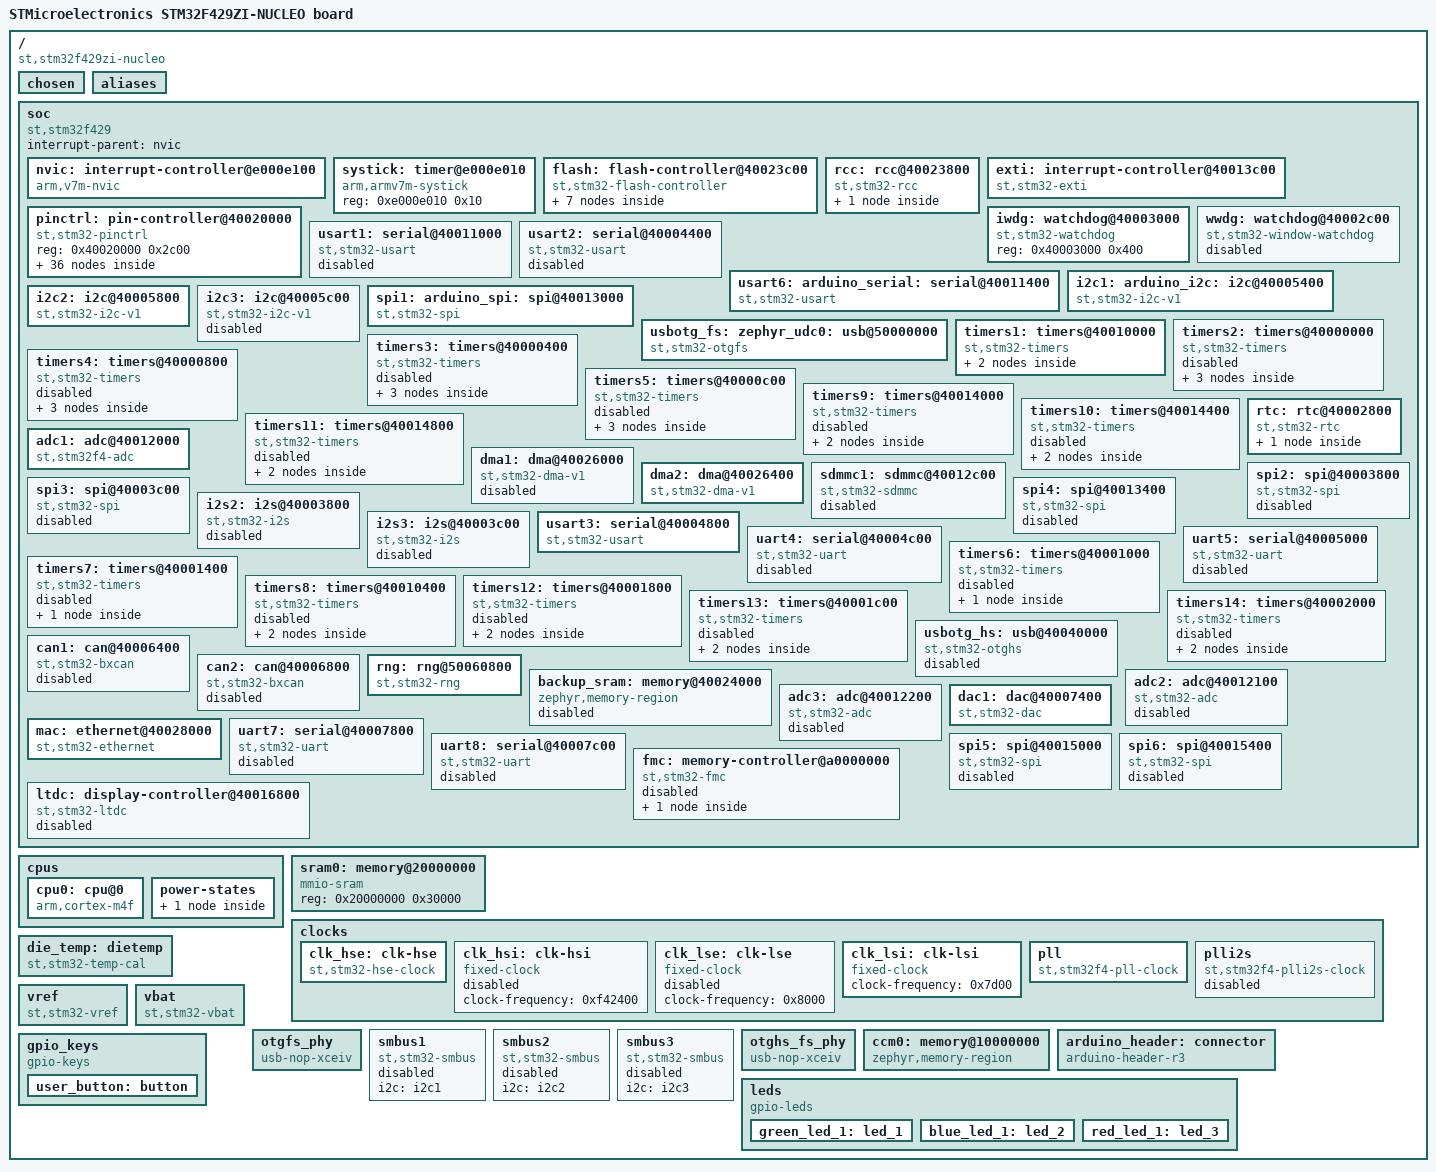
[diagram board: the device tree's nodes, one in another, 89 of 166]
/dts-v1/;

/ {
	#address-cells = < 0x1 >;
	#size-cells = < 0x1 >;
	model = "STMicroelectronics STM32F429ZI-NUCLEO board";
	compatible = "st,stm32f429zi-nucleo";
	chosen {
		zephyr,flash-controller = &flash;
		zephyr,cortex-m-idle-timer = &rtc;
		zephyr,entropy = &rng;
		zephyr,console = &usart3;
		zephyr,shell-uart = &usart3;
		zephyr,sram = &sram0;
		zephyr,flash = &flash0;
		zephyr,ccm = &ccm0;
		zephyr,code-partition = &slot0_partition;
	};
	aliases {
		led0 = &green_led_1;
		led1 = &blue_led_1;
		led2 = &red_led_1;
		sw0 = &user_button;
		watchdog0 = &iwdg;
		die-temp0 = &die_temp;
		volt-sensor0 = &vref;
		volt-sensor1 = &vbat;
	};
	soc {
		#address-cells = < 0x1 >;
		#size-cells = < 0x1 >;
		compatible = "st,stm32f429", "st,stm32f4", "simple-bus";
		interrupt-parent = < &nvic >;
		ranges;
		nvic: interrupt-controller@e000e100 {
			#address-cells = < 0x1 >;
			compatible = "arm,v7m-nvic";
			reg = < 0xe000e100 0xc00 >;
			interrupt-controller;
			#interrupt-cells = < 0x2 >;
			arm,num-irq-priority-bits = < 0x4 >;
			phandle = < 0x1 >;
		};
		systick: timer@e000e010 {
			compatible = "arm,armv7m-systick";
			reg = < 0xe000e010 0x10 >;
		};
		flash: flash-controller@40023c00 {
			compatible = "st,stm32-flash-controller", "st,stm32f4-flash-controller";
			reg = < 0x40023c00 0x400 >;
			interrupts = < 0x4 0x0 >;
			#address-cells = < 0x1 >;
			#size-cells = < 0x1 >;
			flash0: flash@8000000 {
				compatible = "st,stm32f4-nv-flash", "st,stm32-nv-flash", "soc-nv-flash";
				write-block-size = < 0x1 >;
				max-erase-time = < 0xfa0 >;
				reg = < 0x8000000 0x200000 >;
				partitions {
					compatible = "fixed-partitions";
					#address-cells = < 0x1 >;
					#size-cells = < 0x1 >;
					boot_partition: partition@0 {
						label = "mcuboot";
						reg = < 0x0 0x10000 >;
						read-only;
					};
					storage_partition: partition@10000 {
						label = "storage";
						reg = < 0x10000 0x10000 >;
					};
					slot0_partition: partition@20000 {
						label = "image-0";
						reg = < 0x20000 0x40000 >;
					};
					slot1_partition: partition@60000 {
						label = "image-1";
						reg = < 0x60000 0x40000 >;
					};
					scratch_partition: partition@a0000 {
						label = "image-scratch";
						reg = < 0xa0000 0x20000 >;
					};
				};
			};
		};
		rcc: rcc@40023800 {
			compatible = "st,stm32-rcc";
			#clock-cells = < 0x2 >;
			reg = < 0x40023800 0x400 >;
			clocks = < &pll >;
			clock-frequency = < 0xa037a00 >;
			ahb-prescaler = < 0x1 >;
			apb1-prescaler = < 0x4 >;
			apb2-prescaler = < 0x2 >;
			phandle = < 0x3 >;
			rctl: reset-controller {
				compatible = "st,stm32-rcc-rctl";
				#reset-cells = < 0x1 >;
				phandle = < 0x4 >;
			};
		};
		exti: interrupt-controller@40013c00 {
			compatible = "st,stm32-exti";
			interrupt-controller;
			#interrupt-cells = < 0x1 >;
			#address-cells = < 0x1 >;
			reg = < 0x40013c00 0x400 >;
			num-lines = < 0x10 >;
			interrupts = < 0x6 0x0 >, < 0x7 0x0 >, < 0x8 0x0 >, < 0x9 0x0 >, < 0xa 0x0 >, < 0x17 0x0 >, < 0x28 0x0 >;
			interrupt-names = "line0", "line1", "line2", "line3", "line4", "line5-9", "line10-15";
			line-ranges = < 0x0 0x1 >, < 0x1 0x1 >, < 0x2 0x1 >, < 0x3 0x1 >, < 0x4 0x1 >, < 0x5 0x5 >, < 0xa 0x6 >;
		};
		pinctrl: pin-controller@40020000 {
			compatible = "st,stm32-pinctrl";
			#address-cells = < 0x1 >;
			#size-cells = < 0x1 >;
			reg = < 0x40020000 0x2c00 >;
			gpioa: gpio@40020000 {
				compatible = "st,stm32-gpio";
				gpio-controller;
				#gpio-cells = < 0x2 >;
				reg = < 0x40020000 0x400 >;
				clocks = < &rcc 0x30 0x1 >;
				phandle = < 0x28 >;
			};
			gpiob: gpio@40020400 {
				compatible = "st,stm32-gpio";
				gpio-controller;
				#gpio-cells = < 0x2 >;
				reg = < 0x40020400 0x400 >;
				clocks = < &rcc 0x30 0x2 >;
				phandle = < 0x2d >;
			};
			gpioc: gpio@40020800 {
				compatible = "st,stm32-gpio";
				gpio-controller;
				#gpio-cells = < 0x2 >;
				reg = < 0x40020800 0x400 >;
				clocks = < &rcc 0x30 0x4 >;
				phandle = < 0x29 >;
			};
			gpiod: gpio@40020c00 {
				compatible = "st,stm32-gpio";
				gpio-controller;
				#gpio-cells = < 0x2 >;
				reg = < 0x40020c00 0x400 >;
				clocks = < &rcc 0x30 0x8 >;
				phandle = < 0xe >;
			};
			gpioe: gpio@40021000 {
				compatible = "st,stm32-gpio";
				gpio-controller;
				#gpio-cells = < 0x2 >;
				reg = < 0x40021000 0x400 >;
				clocks = < &rcc 0x30 0x10 >;
				phandle = < 0x2c >;
			};
			gpiof: gpio@40021400 {
				compatible = "st,stm32-gpio";
				gpio-controller;
				#gpio-cells = < 0x2 >;
				reg = < 0x40021400 0x400 >;
				clocks = < &rcc 0x30 0x20 >;
				phandle = < 0x2a >;
			};
			gpiog: gpio@40021800 {
				compatible = "st,stm32-gpio";
				gpio-controller;
				#gpio-cells = < 0x2 >;
				reg = < 0x40021800 0x400 >;
				clocks = < &rcc 0x30 0x40 >;
				phandle = < 0x2b >;
			};
			gpioh: gpio@40021c00 {
				compatible = "st,stm32-gpio";
				gpio-controller;
				#gpio-cells = < 0x2 >;
				reg = < 0x40021c00 0x400 >;
				clocks = < &rcc 0x30 0x80 >;
			};
			gpioi: gpio@40022000 {
				compatible = "st,stm32-gpio";
				gpio-controller;
				#gpio-cells = < 0x2 >;
				reg = < 0x40022000 0x400 >;
				clocks = < &rcc 0x30 0x100 >;
			};
			gpioj: gpio@40022400 {
				compatible = "st,stm32-gpio";
				gpio-controller;
				#gpio-cells = < 0x2 >;
				reg = < 0x40022400 0x400 >;
				clocks = < &rcc 0x30 0x200 >;
			};
			gpiok: gpio@40022800 {
				compatible = "st,stm32-gpio";
				gpio-controller;
				#gpio-cells = < 0x2 >;
				reg = < 0x40022800 0x400 >;
				clocks = < &rcc 0x30 0x400 >;
			};
			adc1_in0_pa0: adc1_in0_pa0 {
				pinmux = < 0x10 >;
				phandle = < 0x13 >;
			};
			dac_out1_pa4: dac_out1_pa4 {
				pinmux = < 0x90 >;
				phandle = < 0x18 >;
			};
			eth_crs_dv_pa7: eth_crs_dv_pa7 {
				pinmux = < 0xeb >;
				slew-rate = "very-high-speed";
				phandle = < 0x1e >;
			};
			eth_mdc_pc1: eth_mdc_pc1 {
				pinmux = < 0x42b >;
				slew-rate = "very-high-speed";
				phandle = < 0x19 >;
			};
			eth_mdio_pa2: eth_mdio_pa2 {
				pinmux = < 0x4b >;
				slew-rate = "very-high-speed";
				phandle = < 0x1d >;
			};
			eth_ref_clk_pa1: eth_ref_clk_pa1 {
				pinmux = < 0x2b >;
				slew-rate = "very-high-speed";
				phandle = < 0x1c >;
			};
			eth_rxd0_pc4: eth_rxd0_pc4 {
				pinmux = < 0x48b >;
				slew-rate = "very-high-speed";
				phandle = < 0x1a >;
			};
			eth_rxd1_pc5: eth_rxd1_pc5 {
				pinmux = < 0x4ab >;
				slew-rate = "very-high-speed";
				phandle = < 0x1b >;
			};
			eth_txd0_pg13: eth_txd0_pg13 {
				pinmux = < 0xdab >;
				slew-rate = "very-high-speed";
				phandle = < 0x20 >;
			};
			eth_txd1_pb13: eth_txd1_pb13 {
				pinmux = < 0x3ab >;
				slew-rate = "very-high-speed";
				phandle = < 0x21 >;
			};
			eth_tx_en_pg11: eth_tx_en_pg11 {
				pinmux = < 0xd6b >;
				slew-rate = "very-high-speed";
				phandle = < 0x1f >;
			};
			i2c1_scl_pb8: i2c1_scl_pb8 {
				pinmux = < 0x304 >;
				bias-pull-up;
				drive-open-drain;
				phandle = < 0x7 >;
			};
			i2c2_scl_pb10: i2c2_scl_pb10 {
				pinmux = < 0x344 >;
				bias-pull-up;
				drive-open-drain;
				phandle = < 0x9 >;
			};
			i2c1_sda_pb9: i2c1_sda_pb9 {
				pinmux = < 0x324 >;
				bias-pull-up;
				drive-open-drain;
				phandle = < 0x8 >;
			};
			i2c2_sda_pb11: i2c2_sda_pb11 {
				pinmux = < 0x364 >;
				bias-pull-up;
				drive-open-drain;
				phandle = < 0xa >;
			};
			spi1_miso_pa6: spi1_miso_pa6 {
				pinmux = < 0xc5 >;
				bias-pull-down;
				phandle = < 0xc >;
			};
			spi1_mosi_pa7: spi1_mosi_pa7 {
				pinmux = < 0xe5 >;
				bias-pull-down;
				phandle = < 0xd >;
			};
			spi1_sck_pa5: spi1_sck_pa5 {
				pinmux = < 0xa5 >;
				bias-pull-down;
				slew-rate = "very-high-speed";
				phandle = < 0xb >;
			};
			tim1_ch3_pe13: tim1_ch3_pe13 {
				pinmux = < 0x9a1 >;
				phandle = < 0x12 >;
			};
			usart3_rx_pd9: usart3_rx_pd9 {
				pinmux = < 0x727 >;
				phandle = < 0x16 >;
			};
			usart6_rx_pg9: usart6_rx_pg9 {
				pinmux = < 0xd28 >;
				phandle = < 0x6 >;
			};
			usart3_tx_pd8: usart3_tx_pd8 {
				pinmux = < 0x707 >;
				bias-pull-up;
				phandle = < 0x15 >;
			};
			usart6_tx_pg14: usart6_tx_pg14 {
				pinmux = < 0xdc8 >;
				bias-pull-up;
				phandle = < 0x5 >;
			};
			usb_otg_fs_dm_pa11: usb_otg_fs_dm_pa11 {
				pinmux = < 0x16a >;
				phandle = < 0x10 >;
			};
			usb_otg_fs_dp_pa12: usb_otg_fs_dp_pa12 {
				pinmux = < 0x18a >;
				phandle = < 0x11 >;
			};
		};
		iwdg: watchdog@40003000 {
			compatible = "st,stm32-watchdog";
			reg = < 0x40003000 0x400 >;
			status = "okay";
		};
		wwdg: watchdog@40002c00 {
			compatible = "st,stm32-window-watchdog";
			reg = < 0x40002c00 0x400 >;
			clocks = < &rcc 0x40 0x800 >;
			interrupts = < 0x0 0x7 >;
			status = "disabled";
		};
		usart1: serial@40011000 {
			compatible = "st,stm32-usart", "st,stm32-uart";
			reg = < 0x40011000 0x400 >;
			clocks = < &rcc 0x44 0x10 >;
			resets = < &rctl 0x484 >;
			interrupts = < 0x25 0x0 >;
			status = "disabled";
		};
		usart2: serial@40004400 {
			compatible = "st,stm32-usart", "st,stm32-uart";
			reg = < 0x40004400 0x400 >;
			clocks = < &rcc 0x40 0x20000 >;
			resets = < &rctl 0x411 >;
			interrupts = < 0x26 0x0 >;
			status = "disabled";
		};
		usart6: arduino_serial: serial@40011400 {
			compatible = "st,stm32-usart", "st,stm32-uart";
			reg = < 0x40011400 0x400 >;
			clocks = < &rcc 0x44 0x20 >;
			resets = < &rctl 0x485 >;
			interrupts = < 0x47 0x0 >;
			status = "okay";
			pinctrl-0 = < &usart6_tx_pg14 &usart6_rx_pg9 >;
			pinctrl-names = "default";
			current-speed = < 0x1c200 >;
		};
		i2c1: arduino_i2c: i2c@40005400 {
			compatible = "st,stm32-i2c-v1";
			clock-frequency = < 0x61a80 >;
			#address-cells = < 0x1 >;
			#size-cells = < 0x0 >;
			reg = < 0x40005400 0x400 >;
			clocks = < &rcc 0x40 0x200000 >;
			interrupts = < 0x1f 0x0 >, < 0x20 0x0 >;
			interrupt-names = "event", "error";
			status = "okay";
			pinctrl-0 = < &i2c1_scl_pb8 &i2c1_sda_pb9 >;
			pinctrl-names = "default";
			phandle = < 0x25 >;
		};
		i2c2: i2c@40005800 {
			compatible = "st,stm32-i2c-v1";
			clock-frequency = < 0x61a80 >;
			#address-cells = < 0x1 >;
			#size-cells = < 0x0 >;
			reg = < 0x40005800 0x400 >;
			clocks = < &rcc 0x40 0x400000 >;
			interrupts = < 0x21 0x0 >, < 0x22 0x0 >;
			interrupt-names = "event", "error";
			status = "okay";
			pinctrl-0 = < &i2c2_scl_pb10 &i2c2_sda_pb11 >;
			pinctrl-names = "default";
			phandle = < 0x26 >;
		};
		i2c3: i2c@40005c00 {
			compatible = "st,stm32-i2c-v1";
			clock-frequency = < 0x186a0 >;
			#address-cells = < 0x1 >;
			#size-cells = < 0x0 >;
			reg = < 0x40005c00 0x400 >;
			clocks = < &rcc 0x40 0x800000 >;
			interrupts = < 0x48 0x0 >, < 0x49 0x0 >;
			interrupt-names = "event", "error";
			status = "disabled";
			phandle = < 0x27 >;
		};
		spi1: arduino_spi: spi@40013000 {
			compatible = "st,stm32-spi";
			#address-cells = < 0x1 >;
			#size-cells = < 0x0 >;
			reg = < 0x40013000 0x400 >;
			clocks = < &rcc 0x44 0x1000 >;
			interrupts = < 0x23 0x5 >;
			status = "okay";
			pinctrl-0 = < &spi1_sck_pa5 &spi1_miso_pa6 &spi1_mosi_pa7 >;
			pinctrl-names = "default";
			cs-gpios = < &gpiod 0xe 0x11 >;
		};
		usbotg_fs: zephyr_udc0: usb@50000000 {
			compatible = "st,stm32-otgfs";
			reg = < 0x50000000 0x40000 >;
			interrupts = < 0x43 0x0 >;
			interrupt-names = "otgfs";
			num-bidir-endpoints = < 0x4 >;
			ram-size = < 0x500 >;
			maximum-speed = "full-speed";
			phys = < &otgfs_phy >;
			clocks = < &rcc 0x34 0x80 >, < &rcc 0x5 0xff >;
			status = "okay";
			pinctrl-0 = < &usb_otg_fs_dm_pa11 &usb_otg_fs_dp_pa12 >;
			pinctrl-names = "default";
		};
		timers1: timers@40010000 {
			compatible = "st,stm32-timers";
			reg = < 0x40010000 0x400 >;
			clocks = < &rcc 0x44 0x1 >;
			resets = < &rctl 0x480 >;
			interrupts = < 0x18 0x0 >, < 0x19 0x0 >, < 0x1a 0x0 >, < 0x1b 0x0 >;
			interrupt-names = "brk", "up", "trgcom", "cc";
			st,prescaler = < 0x2710 >;
			status = "okay";
			pwm1: pwm {
				compatible = "st,stm32-pwm";
				status = "okay";
				#pwm-cells = < 0x3 >;
				pinctrl-0 = < &tim1_ch3_pe13 >;
				pinctrl-names = "default";
			};
			qdec {
				compatible = "st,stm32-qdec";
				status = "disabled";
				st,input-filter-level = < 0x0 >;
			};
		};
		timers2: timers@40000000 {
			compatible = "st,stm32-timers";
			reg = < 0x40000000 0x400 >;
			clocks = < &rcc 0x40 0x1 >;
			resets = < &rctl 0x400 >;
			interrupts = < 0x1c 0x0 >;
			interrupt-names = "global";
			st,prescaler = < 0x0 >;
			status = "disabled";
			pwm {
				compatible = "st,stm32-pwm";
				status = "disabled";
				#pwm-cells = < 0x3 >;
			};
			counter {
				compatible = "st,stm32-counter";
				status = "disabled";
			};
			qdec {
				compatible = "st,stm32-qdec";
				status = "disabled";
				st,input-filter-level = < 0x0 >;
			};
		};
		timers3: timers@40000400 {
			compatible = "st,stm32-timers";
			reg = < 0x40000400 0x400 >;
			clocks = < &rcc 0x40 0x2 >;
			resets = < &rctl 0x401 >;
			interrupts = < 0x1d 0x0 >;
			interrupt-names = "global";
			st,prescaler = < 0x0 >;
			status = "disabled";
			pwm {
				compatible = "st,stm32-pwm";
				status = "disabled";
				#pwm-cells = < 0x3 >;
			};
			counter {
				compatible = "st,stm32-counter";
				status = "disabled";
			};
			qdec {
				compatible = "st,stm32-qdec";
				status = "disabled";
				st,input-filter-level = < 0x0 >;
			};
		};
		timers4: timers@40000800 {
			compatible = "st,stm32-timers";
			reg = < 0x40000800 0x400 >;
			clocks = < &rcc 0x40 0x4 >;
			resets = < &rctl 0x402 >;
			interrupts = < 0x1e 0x0 >;
			interrupt-names = "global";
			st,prescaler = < 0x0 >;
			status = "disabled";
			pwm {
				compatible = "st,stm32-pwm";
				status = "disabled";
				#pwm-cells = < 0x3 >;
			};
			counter {
				compatible = "st,stm32-counter";
				status = "disabled";
			};
			qdec {
				compatible = "st,stm32-qdec";
				status = "disabled";
				st,input-filter-level = < 0x0 >;
			};
		};
		timers5: timers@40000c00 {
			compatible = "st,stm32-timers";
			reg = < 0x40000c00 0x400 >;
			clocks = < &rcc 0x40 0x8 >;
			resets = < &rctl 0x403 >;
			interrupts = < 0x32 0x0 >;
			interrupt-names = "global";
			st,prescaler = < 0x0 >;
			status = "disabled";
			pwm {
				compatible = "st,stm32-pwm";
				status = "disabled";
				#pwm-cells = < 0x3 >;
			};
			counter {
				compatible = "st,stm32-counter";
				status = "disabled";
			};
			qdec {
				compatible = "st,stm32-qdec";
				status = "disabled";
				st,input-filter-level = < 0x0 >;
			};
		};
		timers9: timers@40014000 {
			compatible = "st,stm32-timers";
			reg = < 0x40014000 0x400 >;
			clocks = < &rcc 0x44 0x10000 >;
			resets = < &rctl 0x490 >;
			interrupts = < 0x18 0x0 >;
			interrupt-names = "global";
			st,prescaler = < 0x0 >;
			status = "disabled";
			pwm {
				compatible = "st,stm32-pwm";
				status = "disabled";
				#pwm-cells = < 0x3 >;
			};
			counter {
				compatible = "st,stm32-counter";
				status = "disabled";
			};
		};
		timers10: timers@40014400 {
			compatible = "st,stm32-timers";
			reg = < 0x40014400 0x400 >;
			clocks = < &rcc 0x44 0x20000 >;
			resets = < &rctl 0x491 >;
			interrupts = < 0x19 0x0 >;
			interrupt-names = "global";
			st,prescaler = < 0x0 >;
			status = "disabled";
			pwm {
				compatible = "st,stm32-pwm";
				status = "disabled";
				#pwm-cells = < 0x3 >;
			};
			counter {
				compatible = "st,stm32-counter";
				status = "disabled";
			};
		};
		timers11: timers@40014800 {
			compatible = "st,stm32-timers";
			reg = < 0x40014800 0x400 >;
			clocks = < &rcc 0x44 0x40000 >;
			resets = < &rctl 0x492 >;
			interrupts = < 0x1a 0x0 >;
			interrupt-names = "global";
			st,prescaler = < 0x0 >;
			status = "disabled";
			pwm {
				compatible = "st,stm32-pwm";
				status = "disabled";
				#pwm-cells = < 0x3 >;
			};
			counter {
				compatible = "st,stm32-counter";
				status = "disabled";
			};
		};
		rtc: rtc@40002800 {
			compatible = "st,stm32-rtc";
			reg = < 0x40002800 0x400 >;
			interrupts = < 0x29 0x0 >;
			clocks = < &rcc 0x40 0x10000000 >, < &rcc 0x3 0x26870 >;
			prescaler = < 0x8000 >;
			alarms-count = < 0x2 >;
			alrm-exti-line = < 0x11 >;
			status = "okay";
			bbram: backup_regs {
				compatible = "st,stm32-bbram";
				st,backup-regs = < 0x14 >;
				status = "disabled";
			};
		};
		adc1: adc@40012000 {
			compatible = "st,stm32f4-adc", "st,stm32-adc";
			reg = < 0x40012000 0x400 >;
			clocks = < &rcc 0x44 0x100 >;
			interrupts = < 0x12 0x0 >;
			status = "okay";
			#io-channel-cells = < 0x1 >;
			resolutions = < 0x607804 0x517804 0x427804 0x337804 >;
			sampling-times = < 0x3 0xf 0x1c 0x38 0x54 0x70 0x90 0x1e0 >;
			st,adc-clock-source = < 0x1 >;
			st,adc-sequencer = < 0x1 >;
			pinctrl-0 = < &adc1_in0_pa0 >;
			pinctrl-names = "default";
			st,adc-prescaler = < 0x2 >;
			phandle = < 0x24 >;
		};
		dma1: dma@40026000 {
			compatible = "st,stm32-dma-v1";
			#dma-cells = < 0x4 >;
			reg = < 0x40026000 0x400 >;
			interrupts = < 0xb 0x0 0xc 0x0 0xd 0x0 0xe 0x0 0xf 0x0 0x10 0x0 0x11 0x0 0x2f 0x0 >;
			clocks = < &rcc 0x30 0x200000 >;
			status = "disabled";
			phandle = < 0x14 >;
		};
		dma2: dma@40026400 {
			compatible = "st,stm32-dma-v1";
			#dma-cells = < 0x4 >;
			reg = < 0x40026400 0x400 >;
			interrupts = < 0x38 0x0 0x39 0x0 0x3a 0x0 0x3b 0x0 0x3c 0x0 0x44 0x0 0x45 0x0 0x46 0x0 >;
			clocks = < &rcc 0x30 0x400000 >;
			st,mem2mem;
			status = "okay";
		};
		sdmmc1: sdmmc@40012c00 {
			compatible = "st,stm32-sdmmc";
			reg = < 0x40012c00 0x400 >;
			clocks = < &rcc 0x44 0x800 >, < &rcc 0x5 0xff >;
			resets = < &rctl 0x48b >;
			interrupts = < 0x31 0x0 >;
			status = "disabled";
		};
		spi2: spi@40003800 {
			compatible = "st,stm32-spi";
			#address-cells = < 0x1 >;
			#size-cells = < 0x0 >;
			reg = < 0x40003800 0x400 >;
			clocks = < &rcc 0x40 0x4000 >;
			interrupts = < 0x24 0x5 >;
			status = "disabled";
		};
		spi3: spi@40003c00 {
			compatible = "st,stm32-spi";
			#address-cells = < 0x1 >;
			#size-cells = < 0x0 >;
			reg = < 0x40003c00 0x400 >;
			clocks = < &rcc 0x40 0x8000 >;
			interrupts = < 0x33 0x5 >;
			status = "disabled";
		};
		spi4: spi@40013400 {
			compatible = "st,stm32-spi";
			#address-cells = < 0x1 >;
			#size-cells = < 0x0 >;
			reg = < 0x40013400 0x400 >;
			clocks = < &rcc 0x44 0x2000 >;
			interrupts = < 0x54 0x5 >;
			status = "disabled";
		};
		i2s2: i2s@40003800 {
			compatible = "st,stm32-i2s";
			#address-cells = < 0x1 >;
			#size-cells = < 0x0 >;
			reg = < 0x40003800 0x400 >;
			clocks = < &rcc 0x40 0x4000 >;
			interrupts = < 0x24 0x5 >;
			dmas = < &dma1 0x4 0x0 0x400 0x3 &dma1 0x3 0x0 0x400 0x3 >;
			dma-names = "tx", "rx";
			status = "disabled";
		};
		i2s3: i2s@40003c00 {
			compatible = "st,stm32-i2s";
			#address-cells = < 0x1 >;
			#size-cells = < 0x0 >;
			reg = < 0x40003c00 0x400 >;
			clocks = < &rcc 0x40 0x8000 >;
			interrupts = < 0x33 0x5 >;
			dmas = < &dma1 0x5 0x0 0x400 0x3 &dma1 0x0 0x0 0x400 0x3 >;
			dma-names = "tx", "rx";
			status = "disabled";
		};
		usart3: serial@40004800 {
			compatible = "st,stm32-usart", "st,stm32-uart";
			reg = < 0x40004800 0x400 >;
			clocks = < &rcc 0x40 0x40000 >;
			resets = < &rctl 0x412 >;
			interrupts = < 0x27 0x0 >;
			status = "okay";
			pinctrl-0 = < &usart3_tx_pd8 &usart3_rx_pd9 >;
			pinctrl-names = "default";
			current-speed = < 0x1c200 >;
		};
		uart4: serial@40004c00 {
			compatible = "st,stm32-uart";
			reg = < 0x40004c00 0x400 >;
			clocks = < &rcc 0x40 0x80000 >;
			resets = < &rctl 0x413 >;
			interrupts = < 0x34 0x0 >;
			status = "disabled";
		};
		uart5: serial@40005000 {
			compatible = "st,stm32-uart";
			reg = < 0x40005000 0x400 >;
			clocks = < &rcc 0x40 0x100000 >;
			resets = < &rctl 0x414 >;
			interrupts = < 0x35 0x0 >;
			status = "disabled";
		};
		timers6: timers@40001000 {
			compatible = "st,stm32-timers";
			reg = < 0x40001000 0x400 >;
			clocks = < &rcc 0x40 0x10 >;
			resets = < &rctl 0x404 >;
			interrupts = < 0x36 0x0 >;
			interrupt-names = "global";
			st,prescaler = < 0x0 >;
			status = "disabled";
			counter {
				compatible = "st,stm32-counter";
				status = "disabled";
			};
		};
		timers7: timers@40001400 {
			compatible = "st,stm32-timers";
			reg = < 0x40001400 0x400 >;
			clocks = < &rcc 0x40 0x20 >;
			resets = < &rctl 0x405 >;
			interrupts = < 0x37 0x0 >;
			interrupt-names = "global";
			st,prescaler = < 0x0 >;
			status = "disabled";
			counter {
				compatible = "st,stm32-counter";
				status = "disabled";
			};
		};
		timers8: timers@40010400 {
			compatible = "st,stm32-timers";
			reg = < 0x40010400 0x400 >;
			clocks = < &rcc 0x44 0x2 >;
			resets = < &rctl 0x481 >;
			interrupts = < 0x2b 0x0 >, < 0x2c 0x0 >, < 0x2d 0x0 >, < 0x2e 0x0 >;
			interrupt-names = "brk", "up", "trgcom", "cc";
			st,prescaler = < 0x0 >;
			status = "disabled";
			pwm {
				compatible = "st,stm32-pwm";
				status = "disabled";
				#pwm-cells = < 0x3 >;
			};
			qdec {
				compatible = "st,stm32-qdec";
				status = "disabled";
				st,input-filter-level = < 0x0 >;
			};
		};
		timers12: timers@40001800 {
			compatible = "st,stm32-timers";
			reg = < 0x40001800 0x400 >;
			clocks = < &rcc 0x40 0x40 >;
			resets = < &rctl 0x406 >;
			interrupts = < 0x2b 0x0 >;
			interrupt-names = "global";
			st,prescaler = < 0x0 >;
			status = "disabled";
			pwm {
				compatible = "st,stm32-pwm";
				status = "disabled";
				#pwm-cells = < 0x3 >;
			};
			counter {
				compatible = "st,stm32-counter";
				status = "disabled";
			};
		};
		timers13: timers@40001c00 {
			compatible = "st,stm32-timers";
			reg = < 0x40001c00 0x400 >;
			clocks = < &rcc 0x40 0x80 >;
			resets = < &rctl 0x407 >;
			interrupts = < 0x2c 0x0 >;
			interrupt-names = "global";
			st,prescaler = < 0x0 >;
			status = "disabled";
			pwm {
				compatible = "st,stm32-pwm";
				status = "disabled";
				#pwm-cells = < 0x3 >;
			};
			counter {
				compatible = "st,stm32-counter";
				status = "disabled";
			};
		};
		timers14: timers@40002000 {
			compatible = "st,stm32-timers";
			reg = < 0x40002000 0x400 >;
			clocks = < &rcc 0x40 0x100 >;
			resets = < &rctl 0x408 >;
			interrupts = < 0x2d 0x0 >;
			interrupt-names = "global";
			st,prescaler = < 0x0 >;
			status = "disabled";
			pwm {
				compatible = "st,stm32-pwm";
				status = "disabled";
				#pwm-cells = < 0x3 >;
			};
			counter {
				compatible = "st,stm32-counter";
				status = "disabled";
			};
		};
		usbotg_hs: usb@40040000 {
			compatible = "st,stm32-otghs";
			reg = < 0x40040000 0x40000 >;
			interrupts = < 0x4d 0x0 >, < 0x4a 0x0 >, < 0x4b 0x0 >;
			interrupt-names = "otghs", "ep1_out", "ep1_in";
			num-bidir-endpoints = < 0x6 >;
			ram-size = < 0x1000 >;
			maximum-speed = "full-speed";
			phys = < &otghs_fs_phy >;
			clocks = < &rcc 0x30 0x20000000 >, < &rcc 0x5 0xff >;
			status = "disabled";
		};
		can1: can@40006400 {
			compatible = "st,stm32-bxcan";
			reg = < 0x40006400 0x400 >;
			interrupts = < 0x13 0x0 >, < 0x14 0x0 >, < 0x15 0x0 >, < 0x16 0x0 >;
			interrupt-names = "TX", "RX0", "RX1", "SCE";
			clocks = < &rcc 0x40 0x2000000 >;
			status = "disabled";
		};
		can2: can@40006800 {
			compatible = "st,stm32-bxcan";
			reg = < 0x40006800 0x400 >;
			interrupts = < 0x3f 0x0 >, < 0x40 0x0 >, < 0x41 0x0 >, < 0x42 0x0 >;
			interrupt-names = "TX", "RX0", "RX1", "SCE";
			clocks = < &rcc 0x40 0x6000000 >;
			master-can-reg = < 0x40006400 >;
			status = "disabled";
		};
		rng: rng@50060800 {
			compatible = "st,stm32-rng";
			reg = < 0x50060800 0x400 >;
			interrupts = < 0x50 0x0 >;
			clocks = < &rcc 0x34 0x40 >;
			status = "okay";
		};
		backup_sram: memory@40024000 {
			compatible = "zephyr,memory-region", "st,stm32-backup-sram";
			reg = < 0x40024000 0x1000 >;
			clocks = < &rcc 0x30 0x40000 >;
			zephyr,memory-region = "BACKUP_SRAM";
			status = "disabled";
		};
		adc2: adc@40012100 {
			compatible = "st,stm32-adc";
			reg = < 0x40012100 0x50 >;
			clocks = < &rcc 0x44 0x200 >;
			interrupts = < 0x12 0x0 >;
			status = "disabled";
			#io-channel-cells = < 0x1 >;
			resolutions = < 0x607804 0x517804 0x427804 0x337804 >;
			sampling-times = < 0x3 0xf 0x1c 0x38 0x54 0x70 0x90 0x1e0 >;
			st,adc-clock-source = < 0x1 >;
			st,adc-sequencer = < 0x1 >;
		};
		adc3: adc@40012200 {
			compatible = "st,stm32-adc";
			reg = < 0x40012200 0x50 >;
			clocks = < &rcc 0x44 0x400 >;
			interrupts = < 0x12 0x0 >;
			status = "disabled";
			#io-channel-cells = < 0x1 >;
			resolutions = < 0x607804 0x517804 0x427804 0x337804 >;
			sampling-times = < 0x3 0xf 0x1c 0x38 0x54 0x70 0x90 0x1e0 >;
			st,adc-clock-source = < 0x1 >;
			st,adc-sequencer = < 0x1 >;
		};
		dac1: dac@40007400 {
			compatible = "st,stm32-dac";
			reg = < 0x40007400 0x400 >;
			clocks = < &rcc 0x40 0x20000000 >;
			status = "okay";
			#io-channel-cells = < 0x1 >;
			pinctrl-0 = < &dac_out1_pa4 >;
			pinctrl-names = "default";
		};
		mac: ethernet@40028000 {
			compatible = "st,stm32-ethernet";
			reg = < 0x40028000 0x8000 >;
			interrupts = < 0x3d 0x0 >;
			clock-names = "stmmaceth", "mac-clk-tx", "mac-clk-rx", "mac-clk-ptp";
			clocks = < &rcc 0x30 0x2000000 >, < &rcc 0x30 0x4000000 >, < &rcc 0x30 0x8000000 >, < &rcc 0x30 0x10000000 >;
			status = "okay";
			pinctrl-0 = < &eth_mdc_pc1 &eth_rxd0_pc4 &eth_rxd1_pc5 &eth_ref_clk_pa1 &eth_mdio_pa2 &eth_crs_dv_pa7 &eth_tx_en_pg11 &eth_txd0_pg13 &eth_txd1_pb13 >;
			pinctrl-names = "default";
		};
		uart7: serial@40007800 {
			compatible = "st,stm32-uart";
			reg = < 0x40007800 0x400 >;
			clocks = < &rcc 0x40 0x40000000 >;
			resets = < &rctl 0x41e >;
			interrupts = < 0x52 0x0 >;
			status = "disabled";
		};
		uart8: serial@40007c00 {
			compatible = "st,stm32-uart";
			reg = < 0x40007c00 0x400 >;
			clocks = < &rcc 0x40 0x80000000 >;
			resets = < &rctl 0x41f >;
			interrupts = < 0x53 0x0 >;
			status = "disabled";
		};
		spi5: spi@40015000 {
			compatible = "st,stm32-spi";
			#address-cells = < 0x1 >;
			#size-cells = < 0x0 >;
			reg = < 0x40015000 0x400 >;
			clocks = < &rcc 0x44 0x100000 >;
			interrupts = < 0x55 0x5 >;
			status = "disabled";
		};
		spi6: spi@40015400 {
			compatible = "st,stm32-spi";
			#address-cells = < 0x1 >;
			#size-cells = < 0x0 >;
			reg = < 0x40015400 0x400 >;
			clocks = < &rcc 0x44 0x200000 >;
			interrupts = < 0x56 0x5 >;
			status = "disabled";
		};
		fmc: memory-controller@a0000000 {
			compatible = "st,stm32-fmc";
			reg = < 0xa0000000 0x400 >;
			clocks = < &rcc 0x38 0x1 >;
			status = "disabled";
			sdram: sdram {
				compatible = "st,stm32-fmc-sdram";
				#address-cells = < 0x1 >;
				#size-cells = < 0x0 >;
				status = "disabled";
			};
		};
		ltdc: display-controller@40016800 {
			compatible = "st,stm32-ltdc";
			reg = < 0x40016800 0x200 >;
			interrupts = < 0x58 0x0 >, < 0x59 0x0 >;
			interrupt-names = "ltdc", "ltdc_er";
			clocks = < &rcc 0x44 0x4000000 >;
			status = "disabled";
		};
	};
	cpus {
		#address-cells = < 0x1 >;
		#size-cells = < 0x0 >;
		cpu0: cpu@0 {
			device_type = "cpu";
			compatible = "arm,cortex-m4f";
			reg = < 0x0 >;
			cpu-power-states = < &stop >;
		};
		power-states {
			stop: stop {
				compatible = "zephyr,power-state";
				power-state-name = "suspend-to-idle";
				min-residency-us = < 0x190 >;
				exit-latency-us = < 0x12c >;
				phandle = < 0x22 >;
			};
		};
	};
	sram0: memory@20000000 {
		compatible = "mmio-sram";
		reg = < 0x20000000 0x30000 >;
	};
	clocks {
		clk_hse: clk-hse {
			#clock-cells = < 0x0 >;
			compatible = "st,stm32-hse-clock";
			status = "okay";
			hse-bypass;
			clock-frequency = < 0x7a1200 >;
			phandle = < 0x23 >;
		};
		clk_hsi: clk-hsi {
			#clock-cells = < 0x0 >;
			compatible = "fixed-clock";
			clock-frequency = < 0xf42400 >;
			status = "disabled";
		};
		clk_lse: clk-lse {
			#clock-cells = < 0x0 >;
			compatible = "fixed-clock";
			clock-frequency = < 0x8000 >;
			status = "disabled";
		};
		clk_lsi: clk-lsi {
			#clock-cells = < 0x0 >;
			compatible = "fixed-clock";
			clock-frequency = < 0x7d00 >;
			status = "okay";
		};
		pll: pll {
			#clock-cells = < 0x0 >;
			compatible = "st,stm32f4-pll-clock";
			status = "okay";
			div-m = < 0x8 >;
			mul-n = < 0x150 >;
			div-p = < 0x2 >;
			div-q = < 0x7 >;
			clocks = < &clk_hse >;
			phandle = < 0x2 >;
		};
		plli2s: plli2s {
			#clock-cells = < 0x0 >;
			compatible = "st,stm32f4-plli2s-clock";
			status = "disabled";
		};
	};
	die_temp: dietemp {
		compatible = "st,stm32-temp-cal";
		ts-cal1-addr = < 0x1fff7a2c >;
		ts-cal2-addr = < 0x1fff7a2e >;
		ts-cal1-temp = < 0x1e >;
		ts-cal2-temp = < 0x6e >;
		ts-cal-vrefanalog = < 0xce4 >;
		io-channels = < &adc1 0x12 >;
		status = "okay";
	};
	vref: vref {
		compatible = "st,stm32-vref";
		vrefint-cal-addr = < 0x1fff7a2a >;
		vrefint-cal-mv = < 0xce4 >;
		io-channels = < &adc1 0x11 >;
		status = "okay";
	};
	vbat: vbat {
		compatible = "st,stm32-vbat";
		ratio = < 0x4 >;
		io-channels = < &adc1 0x12 >;
		status = "okay";
	};
	otgfs_phy: otgfs_phy {
		compatible = "usb-nop-xceiv";
		#phy-cells = < 0x0 >;
		phandle = < 0xf >;
	};
	smbus1: smbus1 {
		compatible = "st,stm32-smbus";
		#address-cells = < 0x1 >;
		#size-cells = < 0x0 >;
		i2c = < &i2c1 >;
		status = "disabled";
	};
	smbus2: smbus2 {
		compatible = "st,stm32-smbus";
		#address-cells = < 0x1 >;
		#size-cells = < 0x0 >;
		i2c = < &i2c2 >;
		status = "disabled";
	};
	smbus3: smbus3 {
		compatible = "st,stm32-smbus";
		#address-cells = < 0x1 >;
		#size-cells = < 0x0 >;
		i2c = < &i2c3 >;
		status = "disabled";
	};
	otghs_fs_phy: otghs_fs_phy {
		compatible = "usb-nop-xceiv";
		#phy-cells = < 0x0 >;
		phandle = < 0x17 >;
	};
	ccm0: memory@10000000 {
		compatible = "zephyr,memory-region", "st,stm32-ccm";
		reg = < 0x10000000 0x10000 >;
		zephyr,memory-region = "CCM";
	};
	arduino_header: connector {
		compatible = "arduino-header-r3";
		#gpio-cells = < 0x2 >;
		gpio-map-mask = < 0xffffffff 0xffffffc0 >;
		gpio-map-pass-thru = < 0x0 0x3f >;
		gpio-map = < 0x0 0x0 &gpioa 0x3 0x0 >, < 0x1 0x0 &gpioc 0x0 0x0 >, < 0x2 0x0 &gpioc 0x3 0x0 >, < 0x3 0x0 &gpiof 0x3 0x0 >, < 0x4 0x0 &gpiof 0x5 0x0 >, < 0x5 0x0 &gpiof 0xa 0x0 >, < 0x6 0x0 &gpiog 0x9 0x0 >, < 0x7 0x0 &gpiog 0xe 0x0 >, < 0x8 0x0 &gpiof 0xf 0x0 >, < 0x9 0x0 &gpioe 0xd 0x0 >, < 0xa 0x0 &gpiof 0xe 0x0 >, < 0xb 0x0 &gpioe 0xb 0x0 >, < 0xc 0x0 &gpioe 0x9 0x0 >, < 0xd 0x0 &gpiof 0xd 0x0 >, < 0xe 0x0 &gpiof 0xc 0x0 >, < 0xf 0x0 &gpiod 0xf 0x0 >, < 0x10 0x0 &gpiod 0xe 0x0 >, < 0x11 0x0 &gpioa 0x7 0x0 >, < 0x12 0x0 &gpioa 0x6 0x0 >, < 0x13 0x0 &gpioa 0x5 0x0 >, < 0x14 0x0 &gpiob 0x9 0x0 >, < 0x15 0x0 &gpiob 0x8 0x0 >;
	};
	leds: leds {
		compatible = "gpio-leds";
		green_led_1: led_1 {
			gpios = < &gpiob 0x0 0x0 >;
			label = "User LD1";
		};
		blue_led_1: led_2 {
			gpios = < &gpiob 0x7 0x0 >;
			label = "User LD2";
		};
		red_led_1: led_3 {
			gpios = < &gpiob 0xe 0x0 >;
			label = "User LD3";
		};
	};
	gpio_keys {
		compatible = "gpio-keys";
		user_button: button {
			label = "User";
			gpios = < &gpioc 0xd 0x0 >;
			zephyr,code = < 0xb >;
		};
	};
};
